# USB1_CTRL register map
Vendor: Texas Instruments
Peripheral module from a debugger description file (folder am335x).
Registers are 32-bit, read-write, no defined reset value unless marked. A register's access mark holds for its fields unless they carry their own. Offsets are as the file gives them; lines under a group give offsets from that group; [hi:lo] are bit positions; {n}, {i} and the like mark numbered series; 'fields as' and 'values as' point back to an identical list; <NAME> marks a mode.

## USB1_CTRL
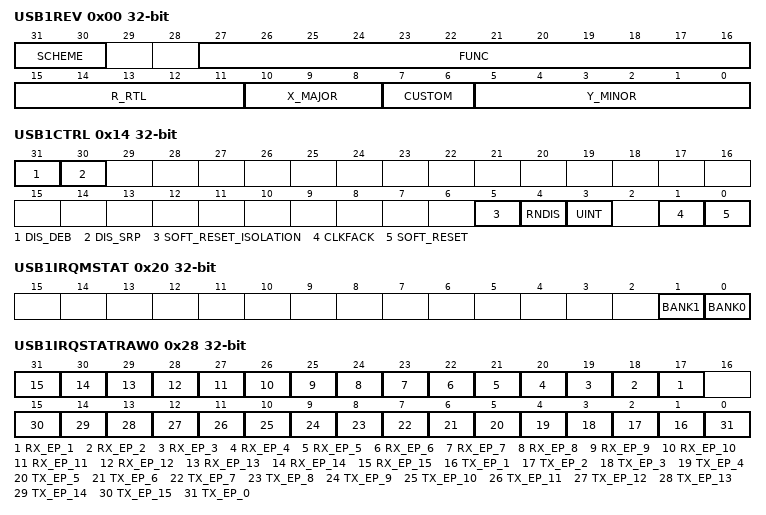
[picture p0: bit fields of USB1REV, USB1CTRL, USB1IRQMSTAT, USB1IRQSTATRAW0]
0x00 USB1REV ro
  [31:30] SCHEME — Used to distinguish between legacy interface scheme and current. 0 = Legacy 1 = Current
  [27:16] FUNC — Function indicates a software compatible module family.
  [15:11] R_RTL — RTL revision. Will vary depending on release.
  [10:8] X_MAJOR — Major revision.
  [7:6] CUSTOM — Custom revision
  [5:0] Y_MINOR — Minor revision. USB1 Revision Register
0x14 USB1CTRL
  [31] DIS_DEB — Disable the VBUS debouncer circuit fix
  [30] DIS_SRP — Disable the OTG Session Request Protocol (SRP) AVALID circuit fix. When enabled (=0) this allows additional time for the VBUS signal to be measured against the VBUS thresholds. The time is specified in the USB0 SRP Fix Time Register.
  [5] SOFT_RESET_ISOLATION — Soft reset isolation. When high this bit forces all USB1 signals that connect to the USBSS to known values during a soft reset via bit 0 of this register. This bit should be set high prior to setting bit 0 and cleared after bit 0 is cleared.
  [4] RNDIS — Global RNDIS mode enable for all endpoints.
  [3] UINT — USB interrupt enable 1 = Legacy 0 = Current (recommended setting); If uint is set high, then the mentor controller generic interrupt for USB[9] will be generated (if enabled). This requires S/W to read the mentor controller's registers to determine which interrupt from USB[0] to USB[7] that occurred.; If uint is set low, then the usb20otg_f module will automatically read the mentor controller's registers and set the appropriate interrupt from USB[0] to USB[7] (if enabled). The generic interrupt for USB[9] will not be generated.
  [1] CLKFACK — Clock stop fast ack enable.
  [0] SOFT_RESET — Software reset of USB1. Write 0 = no action Write 1 = Initiate software reset Read 0 = Reset done, no action Read 1 = Reset ongoing; Both the soft_reset and soft_reset_isolation bits should be asserted simultaneously. This will cause the following sequence of actions to occur over multiple cycles:;; - All USB0 output signals will go to a known constant value via multiplexers. This removes the possibility of timing errors due to the asynchronous resets.; - All USB0 registers will be reset.; - The USB0 resets will be de-asserted.; - The reset isolation multiplexer inputs will be de-selected.; - Both the soft_reset and soft_reset_isolation bits will be automatically cleared.;; Setting only the soft_reset_isolation bit will cause all USB0 output signals to go to a known constant value via multiplexers. This will prevent future access to USB0. To clear this condition the USBSS must be reset via a hard or soft reset.
0x18 USB1STAT ro
  [0] DRVVBUS — Current DRVVBUS value USB1 Status Register
0x20 USB1IRQMSTAT ro
  [1] BANK1 — 0: No events pending from IRQ_STATUS_1 1: At least one event is pending from IRQ_STATUS_1
  [0] BANK0 — 0: No events pending from IRQ_STATUS_0 1: At least one event is pending from IRQ_STATUS_0 USB1 IRQ_MERGED_STATUS Register
0x28 USB1IRQSTATRAW0
  [n+16] RX_EP_{n} (n=1..15) — Interrupt status for RX endpoint {n}
  [n] TX_EP_{n} (n=1..15) — Interrupt status for TX endpoint {n}
  [0] TX_EP_0 — Interrupt status for TX endpoint 0 USB1 IRQ_STATUS_RAW_0 Register
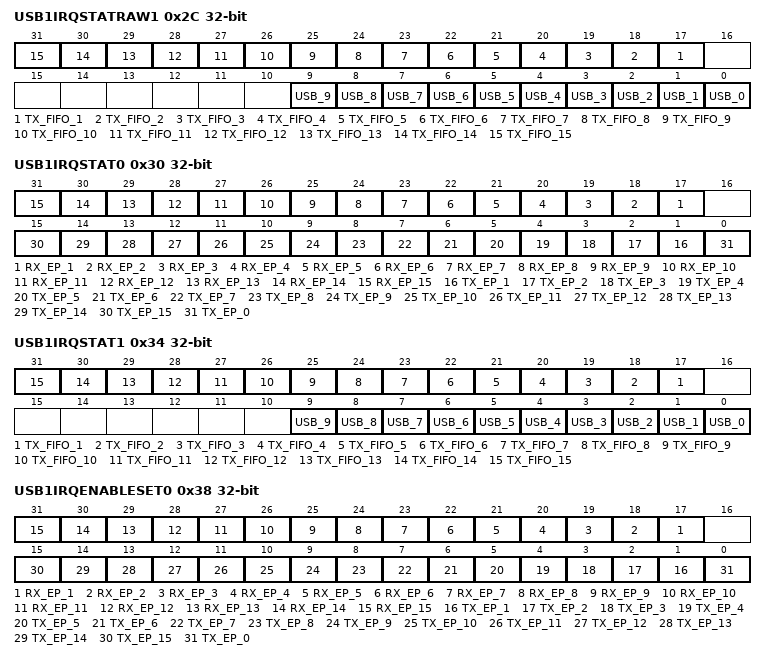
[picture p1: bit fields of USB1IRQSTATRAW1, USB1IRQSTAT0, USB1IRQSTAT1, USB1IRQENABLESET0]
0x2C USB1IRQSTATRAW1
  [n+16] TX_FIFO_{n} (n=1..15) — Interrupt status for TX FIFO endpoint {n}
  [9] USB_9 — Interrupt status for Mentor controller USB_INT generic interrupt
  [8] USB_8 — Interrupt status for DRVVBUS level change
  [7] USB_7 — Interrupt status for VBUS < VBUS valid threshold
  [6] USB_6 — Interrupt status for SRP detected
  [5] USB_5 — Interrupt status for device disconnected (host mode)
  [4] USB_4 — Interrupt status for device connected (host mode)
  [3] USB_3 — Interrupt status for SOF started
  [2] USB_2 — Interrupt status for Reset signaling detected (peripheral mode) Babble detected (host mode)
  [1] USB_1 — Interrupt status for Resume signaling detected
  [0] USB_0 — Interrupt status for Suspend signaling detected USB1 IRQ_STATUS_RAW_1 Register
0x30 USB1IRQSTAT0
  [n+16] RX_EP_{n} (n=1..15) — Interrupt status for RX endpoint {n}
  [n] TX_EP_{n} (n=1..15) — Interrupt status for TX endpoint {n}
  [0] TX_EP_0 — Interrupt status for TX endpoint 0 USB1 IRQ_STATUS_0 Register
0x34 USB1IRQSTAT1
  [n+16] TX_FIFO_{n} (n=1..15) — Interrupt status for TX FIFO endpoint {n}
  [9] USB_9 — Interrupt status for Mentor controller USB_INT generic interrupt
  [8] USB_8 — Interrupt status for DRVVBUS level change
  [7] USB_7 — Interrupt status for VBUS < VBUS valid threshold
  [6] USB_6 — Interrupt status for SRP detected
  [5] USB_5 — Interrupt status for device disconnected (host mode)
  [4] USB_4 — Interrupt status for device connected (host mode)
  [3] USB_3 — Interrupt status for SOF started
  [2] USB_2 — Interrupt status for Reset signaling detected (peripheral mode) Babble detected (host mode)
  [1] USB_1 — Interrupt status for Resume signaling detected
  [0] USB_0 — Interrupt status for Suspend signaling detected USB1 IRQ_STATUS_1 Register
0x38 USB1IRQENABLESET0
  [n+16] RX_EP_{n} (n=1..15) — Interrupt enable for RX endpoint {n}
  [n] TX_EP_{n} (n=1..15) — Interrupt enable for TX endpoint {n}
  [0] TX_EP_0 — Interrupt enable for TX endpoint 0 USB1 IRQ_ENABLE_SET_0 Register
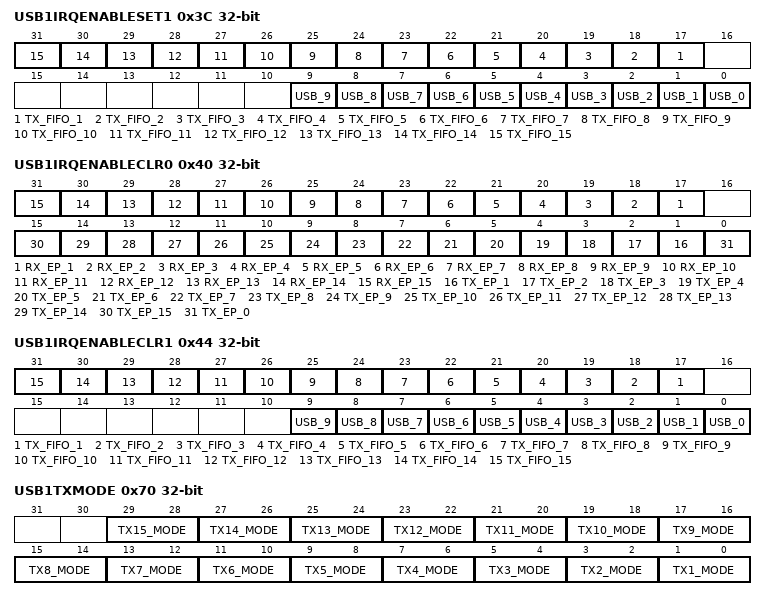
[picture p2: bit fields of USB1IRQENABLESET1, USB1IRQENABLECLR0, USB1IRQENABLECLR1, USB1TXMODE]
0x3C USB1IRQENABLESET1
  [n+16] TX_FIFO_{n} (n=1..15) — Interrupt enable for TX FIFO endpoint {n}
  [9] USB_9 — Interrupt enable for Mentor controller USB_INT generic interrupt
  [8] USB_8 — Interrupt enable for DRVVBUS level change
  [7] USB_7 — Interrupt enable for VBUS < VBUS valid threshold
  [6] USB_6 — Interrupt enable for SRP detected
  [5] USB_5 — Interrupt enable for device disconnected (host mode)
  [4] USB_4 — Interrupt enable for device connected (host mode)
  [3] USB_3 — Interrupt enable for SOF started
  [2] USB_2 — Interrupt enable for Reset signaling detected (peripheral mode) Babble detected (host mode)
  [1] USB_1 — Interrupt enable for Resume signaling detected
  [0] USB_0 — Interrupt enable for Suspend signaling detected USB1 IRQ_ENABLE_SET_1 Register
0x40 USB1IRQENABLECLR0
  [n+16] RX_EP_{n} (n=1..15) — Interrupt enable for RX endpoint {n}
  [n] TX_EP_{n} (n=1..15) — Interrupt enable for TX endpoint {n}
  [0] TX_EP_0 — Interrupt enable for TX endpoint 0 USB1 IRQ_ENABLE_CLR_0 Register
0x44 USB1IRQENABLECLR1
  [n+16] TX_FIFO_{n} (n=1..15) — Interrupt enable for TX FIFO endpoint {n}
  [9] USB_9 — Interrupt enable for Mentor controller USB_INT generic interrupt
  [8] USB_8 — Interrupt enable for DRVVBUS level change
  [7] USB_7 — Interrupt enable for VBUS < VBUS valid threshold
  [6] USB_6 — Interrupt enable for SRP detected
  [5] USB_5 — Interrupt enable for device disconnected (host mode)
  [4] USB_4 — Interrupt enable for device connected (host mode)
  [3] USB_3 — Interrupt enable for SOF started
  [2] USB_2 — Interrupt enable for Reset signaling detected (peripheral mode) Babble detected (host mode)
  [1] USB_1 — Interrupt enable for Resume signaling detected
  [0] USB_0 — Interrupt enable for Suspend signaling detected USB1 IRQ_ENABLE_CLR_1 Register
0x70 USB1TXMODE
  [2n-1:2n-2] TX{n}_MODE (n=2..15) — 00: Transparent Mode on TX endpoint {n-1} 01: RNDIS Mode on TX endpoint {n-1} 10: CDC Mode on TX endpoint {n-1} 11: Generic RNDIS Mode on TX endpoint {n-1}
  [1:0] TX1_MODE — 00: Transparent Mode on TX endpoint 0 01: RNDIS Mode on TX endpoint 0 10: CDC Mode on TX endpoint 0 11: Generic RNDIS Mode on TX endpoint 0 USB1 Tx Mode Registers
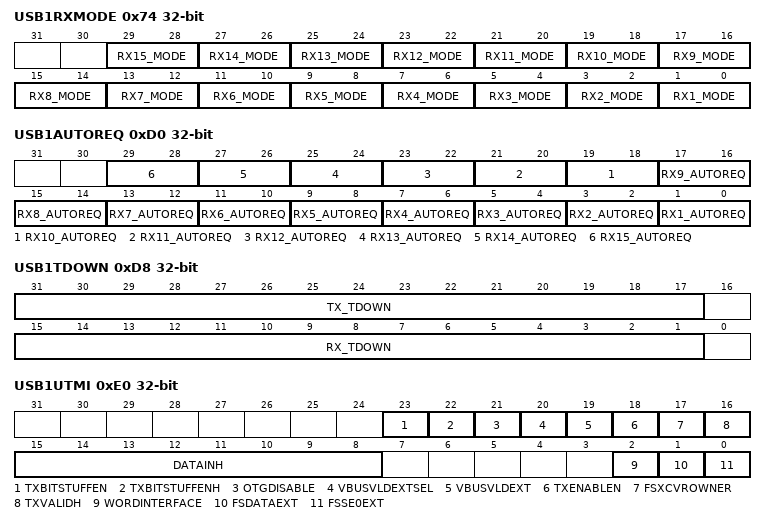
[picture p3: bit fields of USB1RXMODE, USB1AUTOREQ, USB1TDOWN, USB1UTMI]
0x74 USB1RXMODE
  [2n-1:2n-2] RX{n}_MODE (n=2..15) — 00: Transparent Mode on RX endpoint {n-1} 01: RNDIS Mode on RX endpoint {n-1} 10: CDC Mode on RX endpoint {n-1} 11: Generic RNDIS or Infinite Mode on RX endpoint {n-1}
  [1:0] RX1_MODE — 00: Transparent Mode on RX endpoint 0 01: RNDIS Mode on RX endpoint 0 10: CDC Mode on RX endpoint 0 11: Generic RNDIS or Infinite Mode on RX endpoint 0 USB1 Rx Mode Registers
{0x7C+4i} USB1GENRNDISEP{i} (i=1..15)
  [16:0] EP{i}_SIZE — Generic RNDIS packet size. USB1 Generic RNDIS EP N Size Register
0xD0 USB1AUTOREQ
  [2n-1:2n-2] RX{n}_AUTOREQ (n=2..15) — RX endpoint {n-1} Auto Req enable 00 = no auto req 01 = auto req on all but EOP 10 = reserved 11 = auto req always
  [1:0] RX1_AUTOREQ — RX endpoint 0 Auto Req enable 00 = no auto req 01 = auto req on all but EOP 10 = reserved 11 = auto req always USB1 Auto Req Registers
0xD4 USB1SRPFIXTIME
  [31:0] SRPFIXTIME — SRP Fix maximum time in 60 MHz cycles. Default is 700 ms. USB1 SRP Fix Time Register
0xD8 USB1TDOWN
  [31:17] TX_TDOWN — Tx Endpoint Teardown. Write '1' to corresponding bit to set. Read as '0'. Bit 31 = Endpoint 15 ... Bit 17 = Endpoint 1
  [15:1] RX_TDOWN — RX Endpoint Teardown. Write '1' to corresponding bit to set. Read as '0'. Bit 15 = Endpoint 15 ... Bit 1 = Endpoint 1
0xE0 USB1UTMI
  [23] TXBITSTUFFEN — PHY UTMI input for signal txbitstuffen
  [22] TXBITSTUFFENH — PHY UTMI input for signal txbitstuffenh
  [21] OTGDISABLE — PHY UTMI input for signal otgdisable
  [20] VBUSVLDEXTSEL — PHY UTMI input for signal vbusvldextsel
  [19] VBUSVLDEXT — PHY UTMI input for signal vbusvldext
  [18] TXENABLEN — PHY UTMI input for signal txenablen
  [17] FSXCVROWNER — PHY UTMI input for signal fsxcvrowner
  [16] TXVALIDH — PHY UTMI input for signal txvalidh
  [15:8] DATAINH — PHY UTMI input for signal datainh
  [2] WORDINTERFACE — PHY UTMI input for signal wordinterface
  [1] FSDATAEXT — PHY UTMI input for signal fsdataext
  [0] FSSE0EXT — PHY UTMI input for signal fsse0ext USB1 PHY UTMI Register
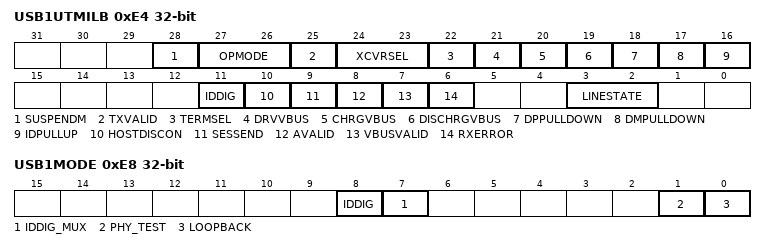
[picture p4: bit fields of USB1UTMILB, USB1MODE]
0xE4 USB1UTMILB access per field
  [28] SUSPENDM ro — loopback test observed value for suspendm
  [27:26] OPMODE ro — loopback test observed value for opmode
  [25] TXVALID ro — loopback test observed value for txvalid
  [24:23] XCVRSEL ro — loopback test observed value for xcvrsel
  [22] TERMSEL ro — loopback test observed value for termsel
  [21] DRVVBUS ro — loopback test observed value for drvvbus
  [20] CHRGVBUS ro — loopback test observed value for chrgvbus
  [19] DISCHRGVBUS ro — loopback test observed value for dischrgvbus
  [18] DPPULLDOWN ro — loopback test observed value for dppulldown
  [17] DMPULLDOWN ro — loopback test observed value for dmpulldown
  [16] IDPULLUP ro — loopback test observed value for idpullup
  [11] IDDIG rw — loopback test value for iddig
  [10] HOSTDISCON rw — loopback test value for hostdiscon
  [9] SESSEND rw — loopback test value for sessend
  [8] AVALID rw — loopback test value for avalid
  [7] VBUSVALID rw — loopback test value for vbusvalid
  [6] RXERROR rw — loopback test value for rxerror
  [3:2] LINESTATE rw — loopback test value for linestate
0xE8 USB1MODE
  [8] IDDIG — MGC input value for iddig 0=A type 1=B type
  [7] IDDIG_MUX — Multiplexer control for IDDIG signal going to the controller. 0 = IDDIG is from PHY1. 1 = IDDIG is from bit8 (IDDIG) of this USB1MODE register.
  [1] PHY_TEST — PHY test 0 = Normal mode 1 = PHY test mode
  [0] LOOPBACK — Loopback test mode 0 = Normal mode 1 = Loopback test mode USB1 Mode Register
